VERSION ""

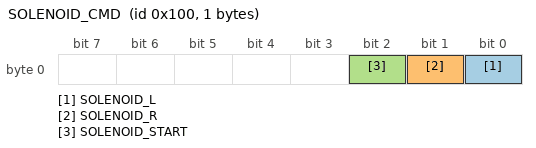
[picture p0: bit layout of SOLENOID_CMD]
BO_ 256 SOLENOID_CMD: 1 XXX
  SG_ SOLENOID_L : 0|1@1+ (1,0) [0|1] "" XXX
  SG_ SOLENOID_R : 1|1@1+ (1,0) [0|1] "" XXX
  SG_ SOLENOID_START : 2|1@1+ (1,0) [0|1] "" XXX

BO_ 257 PINBALL_STATE: 1 XXX
  SG_ HEARTBEAT : 0|1@1+ (1,0) [0|1] "" XXX
